# RCSS_RCM register map
Vendor: Texas Instruments
Peripheral module from a debugger description file (folder am273).
Registers are 32-bit, read-write, no defined reset value unless marked. A register's access mark holds for its fields unless they carry their own. Offsets are as the file gives them; lines under a group give offsets from that group; [hi:lo] are bit positions; {n}, {i} and the like mark numbered series; 'fields as' and 'values as' point back to an identical list; <NAME> marks a mode.

## RCSS_RCM
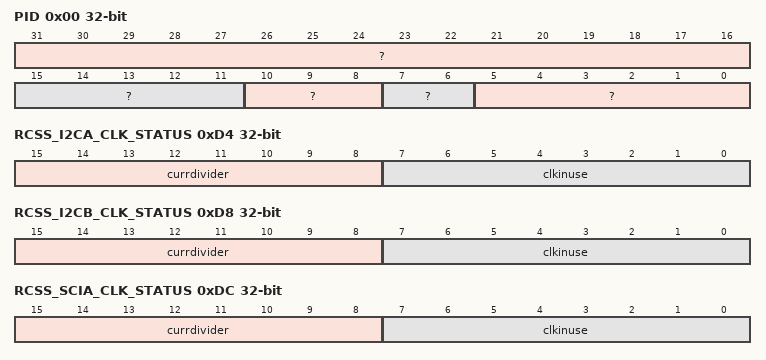
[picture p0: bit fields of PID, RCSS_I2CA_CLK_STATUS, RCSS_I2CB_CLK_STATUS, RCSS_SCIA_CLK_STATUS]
0x00 PID ro
  [31:16] ?, [15:11] ?, [10:8] ?, [7:6] ?, [5:0] ?
0x04 HW_REG0
  [31:0] hwreg — HW Reserved regiser
0x08 HW_REG1
  [31:0] hwreg — HW Reserved regiser
0x0C PREVIOUS_NAME
  [31:0] hwreg — HW Reserved regiser
0x10 HW_REG3
  [31:0] hwreg — HW Reserved regiser
0x14 RCSS_I2CA_CLK_SRC_SEL
  [11:0] clksrcsel — Select line for selecting source clock for RCSS_I2CA. Data should be loaded as multibit. For example: if Clock source 0x5 should be selected then 0x555 should be configured to the register. Refer to TPR12 clock spec for source clock reference
0x18 RCSS_I2CB_CLK_SRC_SEL
  [11:0] clksrcsel — Select line for selecting source clock for RCSS I2CB. Data should be loaded as multibit. For example: if Clock source 0x5 should be selected then 0x555 should be configured to the register. Refer to TPR12 clock spec for source clock reference
0x1C RCSS_SCIA_CLK_SRC_SEL
  [11:0] clksrcsel — Select line for selecting source clock for RCSS SCIA. Data should be loaded as multibit. For example: if Clock source 0x5 should be selected then 0x555 should be configured to the register. Refer to TPR12 clock spec for source clock reference
0x20 RCSS_SPIA_CLK_SRC_SEL
  [11:0] clksrcsel — Select line for selecting source clock for RCSS_SPIA. Data should be loaded as multibit. For example: if Clock source 0x5 should be selected then 0x555 should be configured to the register. Refer to TPR12 clock spec for source clock reference
0x24 RCSS_SPIB_CLK_SRC_SEL
  [11:0] clksrcsel — Select line for selecting source clock for RCSS SPIB. Data should be loaded as multibit. For example: if Clock source 0x5 should be selected then 0x555 should be configured to the register. Refer to TPR12 clock spec for source clock reference
0x28 RCSS_ATL_CLK_SRC_SEL
  [11:0] clksrcsel — Select line for selecting source clock for RCSS ATL CLK Data should be loaded as multibit. For example: if Clock source 0x5 should be selected then 0x555 should be configured to the register. Refer to TPR12 clock spec for source clock reference
0x2C RCSS_MCASPA_REF0_CLK_SRC_SEL
  [11:0] clksrcsel — Select line for selecting source clock for RCSS MCASPA REF0 CLK Data should be loaded as multibit. For example: if Clock source 0x5 should be selected then 0x555 should be configured to the register. Refer to TPR12 clock spec for source clock reference
0x30 RCSS_MCASPA_REF1_CLK_SRC_SEL
  [11:0] clksrcsel — Select line for selecting source clock for RCSS MCASPA REF1 CLK. Data should be loaded as multibit. For example: if Clock source 0x5 should be selected then 0x555 should be configured to the register. Refer to TPR12 clock spec for source clock reference
0x34 RCSS_MCASPA_AUX_CLK_SRC_SEL
  [11:0] clksrcsel — Select line for selecting source clock for RCSS MCASPA AUX CLK Data should be loaded as multibit. For example: if Clock source 0x5 should be selected then 0x555 should be configured to the register. Refer to TPR12 clock spec for source clock reference
0x38 RCSS_MCASPB_REF0_CLK_SRC_SEL
  [11:0] clksrcsel — Select line for selecting source clock for RCSS MCASPB REF0 CLK Data should be loaded as multibit. For example: if Clock source 0x5 should be selected then 0x555 should be configured to the register. Refer to TPR12 clock spec for source clock reference
0x3C RCSS_MCASPB_REF1_CLK_SRC_SEL
  [11:0] clksrcsel — Select line for selecting source clock for RCSS MCASPB REF1 CLK. Data should be loaded as multibit. For example: if Clock source 0x5 should be selected then 0x555 should be configured to the register. Refer to TPR12 clock spec for source clock reference
0x40 RCSS_MCASPB_AUX_CLK_SRC_SEL
  [11:0] clksrcsel — Select line for selecting source clock for RCSS MCASPB AUX CLK Data should be loaded as multibit. For example: if Clock source 0x5 should be selected then 0x555 should be configured to the register. Refer to TPR12 clock spec for source clock reference
0x44 RCSS_MCASPC_REF0_CLK_SRC_SEL
  [11:0] clksrcsel — Select line for selecting source clock for RCSS MCASPC REF0 CLK Data should be loaded as multibit. For example: if Clock source 0x5 should be selected then 0x555 should be configured to the register. Refer to TPR12 clock spec for source clock reference
0x48 RCSS_MCASPC_REF1_CLK_SRC_SEL
  [11:0] clksrcsel — Select line for selecting source clock for RCSS MCASPC REF1 CLK. Data should be loaded as multibit. For example: if Clock source 0x5 should be selected then 0x555 should be configured to the register. Refer to TPR12 clock spec for source clock reference
0x4C RCSS_MCASPC_AUX_CLK_SRC_SEL
  [11:0] clksrcsel — Select line for selecting source clock for RCSS MCASPC AUX CLK Data should be loaded as multibit. For example: if Clock source 0x5 should be selected then 0x555 should be configured to the register. Refer to TPR12 clock spec for source clock reference
0x50 RCSS_I2CA_CLK_DIV_VAL
  [11:0] clkdiv — Divider value for RCSS I2CA selected clock. Data should be loaded as multibit. For example: if divider value of 0x5 should be selected then 0x555 should be configured to the register.
0x54 RCSS_I2CB_CLK_DIV_VAL
  [11:0] clkdiv — Divider value for RCSS I2CB selected clock. Data should be loaded as multibit. For example: if divider value of 0x5 should be selected then 0x555 should be configured to the register.
0x58 RCSS_SCIA_CLK_DIV_VAL
  [11:0] clkdiv — Divider value for RCSS SCIA selected clock. Data should be loaded as multibit. For example: if divider value of 0x5 should be selected then 0x555 should be configured to the register.
0x5C RCSS_SPIA_CLK_DIV_VAL
  [11:0] clkdiv — Divider value for RCSS SPIA selected clock. Data should be loaded as multibit. For example: if divider value of 0x5 should be selected then 0x555 should be configured to the register.
0x60 RCSS_SPIB_CLK_DIV_VAL
  [11:0] clkdiv — Divider value for RCSS SPIB selected clock. Data should be loaded as multibit. For example: if divider value of 0x5 should be selected then 0x555 should be configured to the register.
0x64 RCSS_ATL_CLK_DIV_VAL
  [11:0] clkdiv — Divider value for RCSS ATL CLK selected clock. Data should be loaded as multibit. For example: if divider value of 0x5 should be selected then 0x555 should be configured to the register.
0x68 RCSS_MCASPA_REF0_CLK_DIV_VAL
  [11:0] clkdiv — Divider value for RCSS MCASPA REF0 CLK selected clock. Data should be loaded as multibit. For example: if divider value of 0x5 should be selected then 0x555 should be configured to the register.
0x6C RCSS_MCASPA_REF1_CLK_DIV_VAL
  [11:0] clkdiv — Divider value for RCSS MCASPA REF1 CLK selected clock. Data should be loaded as multibit. For example: if divider value of 0x5 should be selected then 0x555 should be configured to the register.
0x70 RCSS_MCASPA_AUX_CLK_DIV_VAL
  [11:0] clkdiv — Divider value for RCSS MCASPA AUX CLK selected clock. Data should be loaded as multibit. For example: if divider value of 0x5 should be selected then 0x555 should be configured to the register.
0x74 RCSS_MCASPB_REF0_CLK_DIV_VAL
  [11:0] clkdiv — Divider value for RCSS MCASPB REF0 CLK selected clock. Data should be loaded as multibit. For example: if divider value of 0x5 should be selected then 0x555 should be configured to the register.
0x78 RCSS_MCASPB_REF1_CLK_DIV_VAL
  [11:0] clkdiv — Divider value for RCSS MCASPB REF1 CLK selected clock. Data should be loaded as multibit. For example: if divider value of 0x5 should be selected then 0x555 should be configured to the register.
0x7C RCSS_MCASPB_AUX_CLK_DIV_VAL
  [11:0] clkdiv — Divider value for RCSS MCASPB AUX CLK selected clock. Data should be loaded as multibit. For example: if divider value of 0x5 should be selected then 0x555 should be configured to the register.
0x80 RCSS_MCASPC_REF0_CLK_DIV_VAL
  [11:0] clkdiv — Divider value for RCSS MCASPC REF0 CLK selected clock. Data should be loaded as multibit. For example: if divider value of 0x5 should be selected then 0x555 should be configured to the register.
0x84 RCSS_MCASPC_REF1_CLK_DIV_VAL
  [11:0] clkdiv — Divider value for RCSS MCASPC REF1 CLK selected clock. Data should be loaded as multibit. For example: if divider value of 0x5 should be selected then 0x555 should be configured to the register.
0x88 RCSS_MCASPC_AUX_CLK_DIV_VAL
  [11:0] clkdiv — Divider value for RCSS MCASPC AUX CLK selected clock. Data should be loaded as multibit. For example: if divider value of 0x5 should be selected then 0x555 should be configured to the register.
0x8C RCSS_I2CA_CLK_GATE
  [2:0] gated — Clock gatring config for RCSS I2CA Data should be loaded as multibit. Write 3'b000 : Clock is ungated Write 3'b111 : Clock is gated
0x90 RCSS_I2CB_CLK_GATE
  [2:0] gated — Clock gatring config for RCSS I2CB Data should be loaded as multibit. Write 3'b000 : Clock is ungated Write 3'b111 : Clock is gated
0x94 RCSS_SCIA_CLK_GATE
  [2:0] gated — Clock gatring config for RCSS SCIA Data should be loaded as multibit. Write 3'b000 : Clock is ungated Write 3'b111 : Clock is gated
0x98 RCSS_SPIA_CLK_GATE
  [2:0] gated — Clock gatring config for RCSS SPIA Data should be loaded as multibit. Write 3'b000 : Clock is ungated Write 3'b111 : Clock is gated
0x9C RCSS_SPIB_CLK_GATE
  [2:0] gated — Clock gatring config for RCSS SPIB Data should be loaded as multibit. Write 3'b000 : Clock is ungated Write 3'b111 : Clock is gated
0xA0 RCSS_ATL_CLK_GATE
  [2:0] gated — Clock gatring config for RCSS ATL CLK Data should be loaded as multibit. Write 3'b000 : Clock is ungated Write 3'b111 : Clock is gated
0xA4 RCSS_MCASPA_REF0_CLK_GATE
  [2:0] gated — Clock gatring config for RCSS MCASPA REF0 CLK Data should be loaded as multibit. Write 3'b000 : Clock is ungated Write 3'b111 : Clock is gated
0xA8 RCSS_MCASPA_REF1_CLK_GATE
  [2:0] gated — Clock gatring config for RCSS MCASPA REF1 CLK Data should be loaded as multibit. Write 3'b000 : Clock is ungated Write 3'b111 : Clock is gated
0xAC RCSS_MCASPA_AUX_CLK_GATE
  [2:0] gated — Clock gatring config for RCSS MCASPA AUX CLK Data should be loaded as multibit. Write 3'b000 : Clock is ungated Write 3'b111 : Clock is gated
0xB0 RCSS_MCASPB_REF0_CLK_GATE
  [2:0] gated — Clock gatring config for RCSS MCASPB REF0 CLK Data should be loaded as multibit. Write 3'b000 : Clock is ungated Write 3'b111 : Clock is gated
0xB4 RCSS_MCASPB_REF1_CLK_GATE
  [2:0] gated — Clock gatring config for RCSS MCASPB REF1 CLK Data should be loaded as multibit. Write 3'b000 : Clock is ungated Write 3'b111 : Clock is gated
0xB8 RCSS_MCASPB_AUX_CLK_GATE
  [2:0] gated — Clock gatring config for RCSS MCASPB AUX CLK Data should be loaded as multibit. Write 3'b000 : Clock is ungated Write 3'b111 : Clock is gated
0xBC RCSS_MCASPC_REF0_CLK_GATE
  [2:0] gated — Clock gatring config for RCSS MCASPC REF0 CLK Data should be loaded as multibit. Write 3'b000 : Clock is ungated Write 3'b111 : Clock is gated
0xC0 RCSS_MCASPC_REF1_CLK_GATE
  [2:0] gated — Clock gatring config for RCSS MCASPC REF1 CLK Data should be loaded as multibit. Write 3'b000 : Clock is ungated Write 3'b111 : Clock is gated
0xC4 RCSS_MCASPC_AUX_CLK_GATE
  [2:0] gated — Clock gatring config for RCSS MCASPC AUX CLK Data should be loaded as multibit. Write 3'b000 : Clock is ungated Write 3'b111 : Clock is gated
0xC8 RCSS_ECAP_SYS_CLK_GATE
  [2:0] gated — Clock gatring config for RCSS ECAP Data should be loaded as multibit. Write 3'b000 : Clock is ungated Write 3'b111 : Clock is gated
0xCC RCSS_CSI2A_SYS_CLK_GATE
  [2:0] gated — Clock gatring config for RCSS CSI2A Data should be loaded as multibit. Write 3'b000 : Clock is ungated Write 3'b111 : Clock is gated
0xD0 RCSS_CSI2B_SYS_CLK_GATE
  [2:0] gated — Clock gatring config for RCSS CSI2B Data should be loaded as multibit. Write 3'b000 : Clock is ungated Write 3'b111 : Clock is gated
0xD4 RCSS_I2CA_CLK_STATUS ro
  [15:8] currdivider — Status shows the current divider value choosen for RCSS I2CA Clock
  [7:0] clkinuse — Status shows the source clock slected for RCSS I2CA Clock
0xD8 RCSS_I2CB_CLK_STATUS ro
  [15:8] currdivider — Status shows the current divider value choosen for RCSS I2CB Clock
  [7:0] clkinuse — Status shows the source clock slected for RCSS I2CB Clock
0xDC RCSS_SCIA_CLK_STATUS ro
  [15:8] currdivider — Status shows the current divider value choosen for RCSS SCIA Clock
  [7:0] clkinuse — Status shows the source clock slected for RCSS SCIA Clock
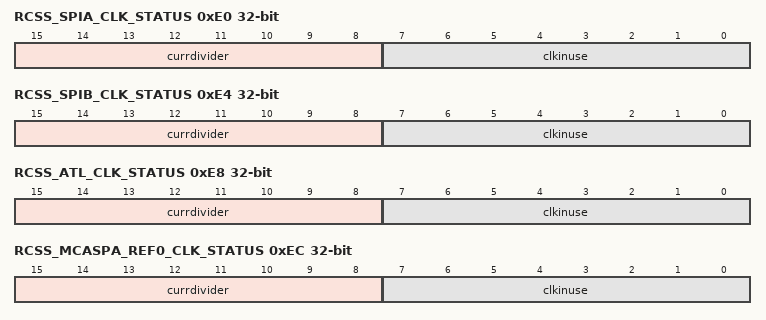
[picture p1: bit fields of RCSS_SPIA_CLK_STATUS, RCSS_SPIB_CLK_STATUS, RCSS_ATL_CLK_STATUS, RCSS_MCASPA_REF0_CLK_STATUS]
0xE0 RCSS_SPIA_CLK_STATUS ro
  [15:8] currdivider — Status shows the current divider value choosen for RCSS SPIA Clock
  [7:0] clkinuse — Status shows the source clock slected for RCSS SPIA Clock
0xE4 RCSS_SPIB_CLK_STATUS ro
  [15:8] currdivider — Status shows the current divider value choosen for RCSS SPIB Clock
  [7:0] clkinuse — Status shows the source clock slected for RCSS SPIB Clock
0xE8 RCSS_ATL_CLK_STATUS ro
  [15:8] currdivider — Status shows the current divider value choosen for RCSS ATL_CLK Clock
  [7:0] clkinuse — Status shows the source clock slected for RCSS ATL_CLK Clock
0xEC RCSS_MCASPA_REF0_CLK_STATUS ro
  [15:8] currdivider — Status shows the current divider value choosen for RCSS MCASPA_REF0_CLK Clock
  [7:0] clkinuse — Status shows the source clock slected for RCSS MCASPA_REF0_CLK Clock
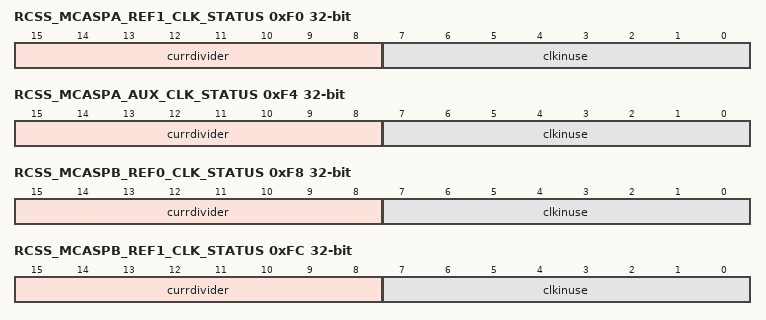
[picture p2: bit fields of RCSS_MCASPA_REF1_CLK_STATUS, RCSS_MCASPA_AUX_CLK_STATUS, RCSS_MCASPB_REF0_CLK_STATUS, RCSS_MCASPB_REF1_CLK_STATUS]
0xF0 RCSS_MCASPA_REF1_CLK_STATUS ro
  [15:8] currdivider — Status shows the current divider value choosen for RCSS MCASPA_REF1_CLK Clock
  [7:0] clkinuse — Status shows the source clock slected for RCSS MCASPA_REF1_CLK Clock
0xF4 RCSS_MCASPA_AUX_CLK_STATUS ro
  [15:8] currdivider — Status shows the current divider value choosen for RCSS MCASPA_AUX_CLK Clock
  [7:0] clkinuse — Status shows the source clock slected for RCSS MCASPA_AUX_CLK Clock
0xF8 RCSS_MCASPB_REF0_CLK_STATUS ro
  [15:8] currdivider — Status shows the current divider value choosen for RCSS MCASPB_REF0_CLK Clock
  [7:0] clkinuse — Status shows the source clock slected for RCSS MCASPB_REF0_CLK Clock
0xFC RCSS_MCASPB_REF1_CLK_STATUS ro
  [15:8] currdivider — Status shows the current divider value choosen for RCSS MCASPB_REF1_CLK Clock
  [7:0] clkinuse — Status shows the source clock slected for RCSS MCASPB_REF1_CLK Clock
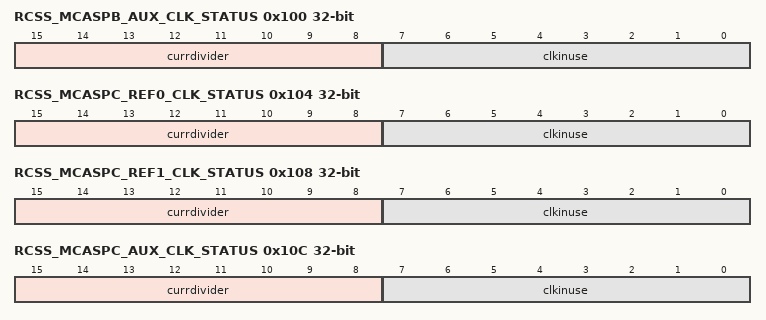
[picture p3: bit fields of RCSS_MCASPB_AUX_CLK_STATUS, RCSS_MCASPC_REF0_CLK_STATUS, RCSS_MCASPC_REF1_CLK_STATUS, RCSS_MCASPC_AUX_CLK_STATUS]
0x100 RCSS_MCASPB_AUX_CLK_STATUS ro
  [15:8] currdivider — Status shows the current divider value choosen for RCSS MCASPB_AUX_CLK Clock
  [7:0] clkinuse — Status shows the source clock slected for RCSS MCASPB_AUX_CLK Clock
0x104 RCSS_MCASPC_REF0_CLK_STATUS ro
  [15:8] currdivider — Status shows the current divider value choosen for RCSS MCASPC_REF0_CLK Clock
  [7:0] clkinuse — Status shows the source clock slected for RCSS MCASPC_REF0_CLK Clock
0x108 RCSS_MCASPC_REF1_CLK_STATUS ro
  [15:8] currdivider — Status shows the current divider value choosen for RCSS MCASPC_REF1_CLK Clock
  [7:0] clkinuse — Status shows the source clock slected for RCSS MCASPC_REF1_CLK Clock
0x10C RCSS_MCASPC_AUX_CLK_STATUS ro
  [15:8] currdivider — Status shows the current divider value choosen for RCSS MCASPC_AUX_CLK Clock
  [7:0] clkinuse — Status shows the source clock slected for RCSS MCASPC_AUX_CLK Clock
0x110 RCSS_ECAP_RST_CTRL
  [2:0] assert — This feature is for debug pupose only. software need to ensure the correct state of Device/IP before configuring this reset control for RCSS ECAP Data should be loaded as multibit. Write 3'b000: Reset is not asserted by SW. There could be another reset source which could reset the module. Refer to RCM spec for more details Write 3'b111 : Reset is asserted by SW
0x114 RCSS_CSI2A_RST_CTRL
  [2:0] assert — This feature is for debug pupose only. software need to ensure the correct state of Device/IP before configuring this reset control for RCSS CSI2A Data should be loaded as multibit. Write 3'b000: Reset is not asserted by SW. There could be another reset source which could reset the module. Refer to RCM spec for more details Write 3'b111 : Reset is asserted by SW
0x118 RCSS_CSI2B_RST_CTRL
  [2:0] assert — This feature is for debug pupose only. software need to ensure the correct state of Device/IP before configuring this reset control for RCSS CSI2B Data should be loaded as multibit. Write 3'b000: Reset is not asserted by SW. There could be another reset source which could reset the module. Refer to RCM spec for more details Write 3'b111 : Reset is asserted by SW
0x11C RCSS_I2CA_RST_CTRL
  [2:0] assert — This feature is for debug pupose only. software need to ensure the correct state of Device/IP before configuring this reset control for RCSS I2CA Data should be loaded as multibit. Write 3'b000: Reset is not asserted by SW. There could be another reset source which could reset the module. Refer to RCM spec for more details Write 3'b111 : Reset is asserted by SW
0x120 RCSS_I2CB_RST_CTRL
  [2:0] assert — This feature is for debug pupose only. software need to ensure the correct state of Device/IP before configuring this reset control for RCSS I2CB Data should be loaded as multibit. Write 3'b000: Reset is not asserted by SW. There could be another reset source which could reset the module. Refer to RCM spec for more details Write 3'b111 : Reset is asserted by SW
0x124 RCSS_SCIA_RST_CTRL
  [2:0] assert — This feature is for debug pupose only. software need to ensure the correct state of Device/IP before configuring this reset control for RCSS SCIA Data should be loaded as multibit. Write 3'b000: Reset is not asserted by SW. There could be another reset source which could reset the module. Refer to RCM spec for more details Write 3'b111 : Reset is asserted by SW
0x128 RCSS_SPIA_RST_CTRL
  [2:0] assert — This feature is for debug pupose only. software need to ensure the correct state of Device/IP before configuring this reset control for RCSS SPIA Data should be loaded as multibit. Write 3'b000: Reset is not asserted by SW. There could be another reset source which could reset the module. Refer to RCM spec for more details Write 3'b111 : Reset is asserted by SW
0x12C RCSS_SPIB_RST_CTRL
  [2:0] assert — This feature is for debug pupose only. software need to ensure the correct state of Device/IP before configuring this reset control for RCSS SPIB Data should be loaded as multibit. Write 3'b000: Reset is not asserted by SW. There could be another reset source which could reset the module. Refer to RCM spec for more details Write 3'b111 : Reset is asserted by SW
0x130 RCSS_MCASPA_RST_CTRL
  [2:0] assert — This feature is for debug pupose only. software need to ensure the correct state of Device/IP before configuring this reset control for RCSS MCASPA Data should be loaded as multibit. Write 3'b000: Reset is not asserted by SW. There could be another reset source which could reset the module. Refer to RCM spec for more details Write 3'b111 : Reset is asserted by SW
0x134 RCSS_MCASPB_RST_CTRL
  [2:0] assert — This feature is for debug pupose only. software need to ensure the correct state of Device/IP before configuring this reset control for RCSS MCASPB Data should be loaded as multibit. Write 3'b000: Reset is not asserted by SW. There could be another reset source which could reset the module. Refer to RCM spec for more details Write 3'b111 : Reset is asserted by SW
0x138 RCSS_MCASPC_RST_CTRL
  [2:0] assert — This feature is for debug pupose only. software need to ensure the correct state of Device/IP before configuring this reset control for RCSS MCASPC Data should be loaded as multibit. Write 3'b000: Reset is not asserted by SW. There could be another reset source which could reset the module. Refer to RCM spec for more details Write 3'b111 : Reset is asserted by SW
0x13C RCSS_GIO_RST_CTRL
  [2:0] assert — This feature is for debug pupose only. software need to ensure the correct state of Device/IP before configuring this reset control for RCSS GIO Data should be loaded as multibit. Write 3'b000: Reset is not asserted by SW. There could be another reset source which could reset the module. Refer to RCM spec for more details Write 3'b111 : Reset is asserted by SW
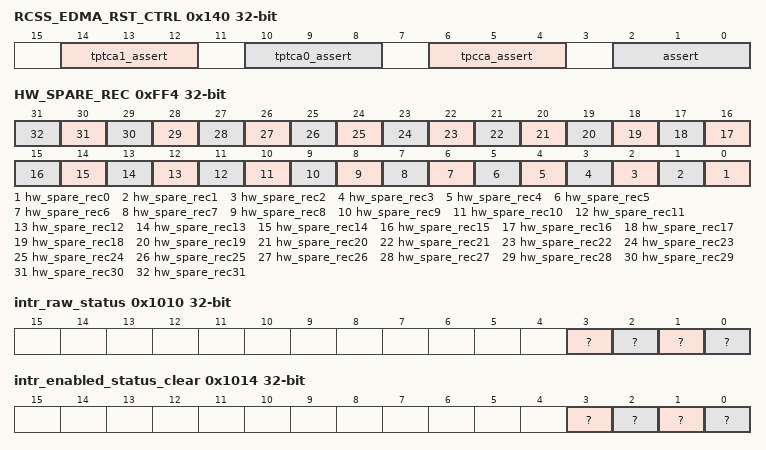
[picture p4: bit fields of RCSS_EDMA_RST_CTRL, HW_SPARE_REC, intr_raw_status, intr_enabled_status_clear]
0x140 RCSS_EDMA_RST_CTRL
  [14:12] tptca1_assert — writing '111' will reset MSS_TPTCA0
  [10:8] tptca0_assert — writing '111' will reset MSS_TPCCA
  [6:4] tpcca_assert — This feature is for debug pupose only. software need to ensure the correct state of Device/IP before configuring this reset control for RCSS EDMA Data should be loaded as multibit. Write 3'b000: Reset is not asserted by SW. There could be another reset source which could reset the module. Refer to RCM spec for more details Write 3'b111 : Reset is asserted by SW
  [2:0] assert — This feature is for debug pupose only. software need to ensure the correct state of Device/IP before configuring this reset control for RCSS EDMA Data should be loaded as multibit. Write 3'b000: Reset is not asserted by SW. There could be another reset source which could reset the module. Refer to RCM spec for more details Write 3'b111 : Reset is asserted by SW
{0xFD0+4i} HW_SPARE_RW{i} (i=0..3)
  [31:0] hw_spare_rw{i} — Reserved for HW R&D
{0xFE0+4i} HW_SPARE_RO{i} ro (i=0..3)
  [31:0] hw_spare_ro{i} — Reserved for HW R&D
0xFF0 HW_SPARE_WPH
  [31:0] hw_spare_wph — Reserved for HW R&D
0xFF4 HW_SPARE_REC
  [n] hw_spare_rec{n} (n=0..31) — Reserved for HW R&D
0x1008 LOCK0_KICK0 — - KICK0 component
  [31:0] ?
0x100C LOCK0_KICK1 — - KICK1 component
  [31:0] ?
0x1010 intr_raw_status — Interrupt Raw Status/Set Register
  [3] ? — Proxy0 access violation error. Raw status is read. Write a 1 to set the status. Writing a 0 has no effect.
  [2] ? — Kick access violation error. Raw status is read. Write a 1 to set the status. Writing a 0 has no effect.
  [1] ? — Addressing violation error. Raw status is read. Write a 1 to set the status. Writing a 0 has no effect.
  [0] ? — Protection violation error. Raw status is read. Write a 1 to set the status. Writing a 0 has no effect.
0x1014 intr_enabled_status_clear — Interrupt Enabled Status/Clear register
  [3] ? — Proxy0 access violation error. Enabled status is read. Write a 1 to clear the status. Writing a 0 has no effect.
  [2] ? — Kick access violation error. Enabled status is read. Write a 1 to clear the status. Writing a 0 has no effect.
  [1] ? — Addressing violation error. Enabled status is read. Write a 1 to clear the status. Writing a 0 has no effect.
  [0] ? — Protection violation error. Enabled status is read. Write a 1 to clear the status. Writing a 0 has no effect.
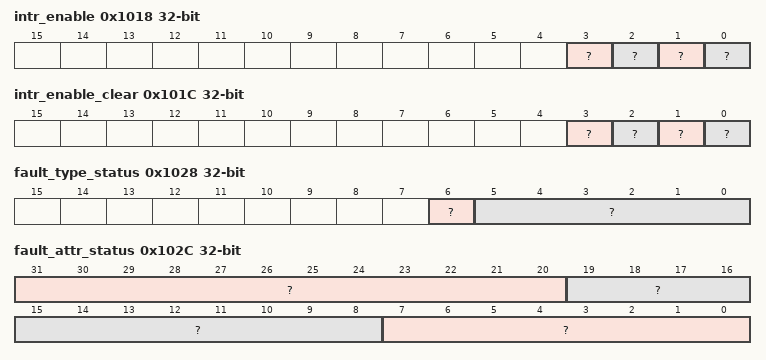
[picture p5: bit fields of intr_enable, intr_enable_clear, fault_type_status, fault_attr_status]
0x1018 intr_enable — Interrupt Enable register
  [3] ? — Proxy0 access violation error enable. Write a 1 to set the enable. Writing a 0 has no effect.
  [2] ? — Kick access violation error enable. Write a 1 to set the enable. Writing a 0 has no effect.
  [1] ? — Addressing violation error enable. Write a 1 to set the enable. Writing a 0 has no effect.
  [0] ? — Protection violation error enable. Write a 1 to set the enable. Writing a 0 has no effect.
0x101C intr_enable_clear — Interrupt Enable Clear register
  [3] ? — Proxy0 access violation error enable clear. Write a 1 to clear the enable. Writing a 0 has no effect.
  [2] ? — Kick access violation error enable clear. Write a 1 to clear the enable. Writing a 0 has no effect.
  [1] ? — Addressing violation error enable clear. Write a 1 to clear the enable. Writing a 0 has no effect.
  [0] ? — Protection violation error enable clear. Write a 1 to clear the enable. Writing a 0 has no effect.
0x1020 eoi
  [7:0] ? — EOI vector value. Write this with interrupt distribution value in the chip.
0x1024 fault_address ro
  [31:0] ? — Fault Address.
0x1028 fault_type_status ro
  [6] ? — Non-secure access.
  [5:0] ? — Fault Type 10_0000 = Supervisor read fault - priv = 1 dir = 1 dtype != 1 01_0000 = Supervisor write fault - priv = 1 dir = 0 00_1000 = Supervisor execute fault - priv = 1 dir = 1 dtype = 1 00_0100 = User read fault - priv = 0 dir = 1 dtype = 1 00_0010 = User write fault - priv = 0 dir = 0 00_0001 = User execute fault - priv = 0 dir = 1 dtype = 1 00_0000 = No fault
0x102C fault_attr_status ro — Fault Attribute Status register
  [31:20] ? — XID.
  [19:8] ? — Route ID.
  [7:0] ? — Privilege ID.
0x1030 fault_clear wo
  [0] ? — Fault clear. Writing a 1 clears the current fault. Writing a 0 has no effect.
